# GIO register map
Vendor: Texas Instruments
Peripheral module from a debugger description file (folder ucd3138064).
Registers are 32-bit, access not given, no defined reset value unless marked. A register's access mark holds for its fields unless they carry their own. Offsets are as the file gives them; lines under a group give offsets from that group; [hi:lo] are bit positions; {n}, {i} and the like mark numbered series; 'fields as' and 'values as' point back to an identical list; <NAME> marks a mode.

## GIO
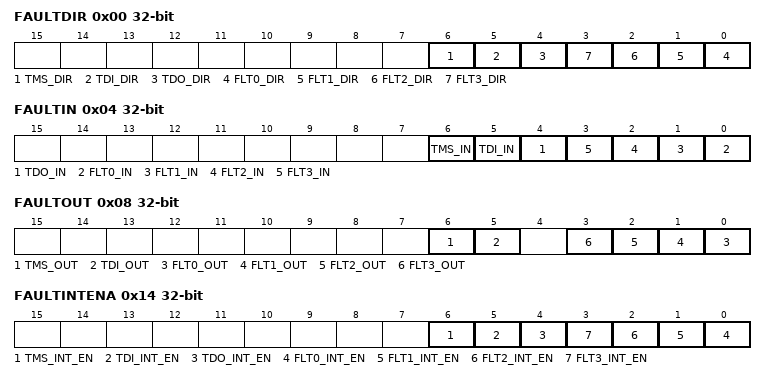
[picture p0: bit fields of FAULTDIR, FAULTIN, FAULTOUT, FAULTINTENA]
0x00 FAULTDIR — Fault Port Direction Register
  [6] TMS_DIR rw — TMS Pin Direction in GPIO Mode
  [5] TDI_DIR rw — TDI Pin Direction in GPIO Mode
  [4] TDO_DIR rw — TDO Pin Direction in GPIO Mode
  [n] FLT{n}_DIR rw (n=0..3) — FAULT[{n}] Pin Direction
0x04 FAULTIN — Fault Port Input Data
  [6] TMS_IN ro — TMS Input Value in GPIO Mode
  [5] TDI_IN ro — TDI Input Value in GPIO Mode
  [4] TDO_IN ro — TDO Input Value in GPIO Mode
  [n] FLT{n}_IN ro (n=0..3) — FAULT[{n}] Input Value
0x08 FAULTOUT — Fault Port Output Data
  [6] TMS_OUT rw — TMS pin output data
  [5] TDI_OUT rw — TDI pin output data
  [n] FLT{n}_OUT rw (n=0..3) — FAULT[{n}] pin output data
0x14 FAULTINTENA — Fault Port Interrupt Enable Register
  [6] TMS_INT_EN rw — TMS pin interrupt enable
  [5] TDI_INT_EN rw — TDI pin interrupt enable
  [4] TDO_INT_EN rw — TDO pin interrupt enable
  [n] FLT{n}_INT_EN rw (n=0..3) — FAULT[{n}] pin interrupt enable
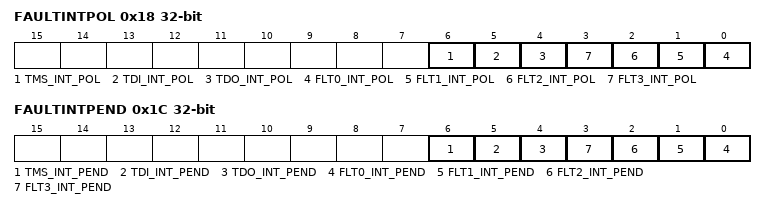
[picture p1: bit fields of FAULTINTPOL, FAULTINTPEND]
0x18 FAULTINTPOL — Fault Port Interrupt Polarity Register
  [6] TMS_INT_POL rw — TMS pin interrupt polarity
  [5] TDI_INT_POL rw — TDI pin interrupt polarity
  [4] TDO_INT_POL rw — TDO pin interrupt polarity
  [n] FLT{n}_INT_POL rw (n=0..3) — FAULT[{n}] pin interrupt polarity
0x1C FAULTINTPEND — Fault Port Interrupt Pending Register
  [6] TMS_INT_PEND rw — TMS pin interrupt flag
  [5] TDI_INT_PEND rw — TDI pin interrupt flag
  [4] TDO_INT_PEND rw — TDO pin interrupt flag
  [n] FLT{n}_INT_PEND rw (n=0..3) — FAULT[{n}] pin interrupt flag
0x20 EXTINTDIR — External Interrupt Direction Register
  [0] EXT_INT_DIR rw — External Interrupt Pin Direction
0x24 EXTINTIN — External Interrupt Input Data
  [0] EXT_INT_IN ro — External Interrupt Pin Input Value
0x28 EXTINTOUT — External Interrupt Output Data
  [0] EXTINT_OUT rw — External Interrupt pin output data
0x34 EXTINTENA — External Interrupt Enable Register
  [0] EXT_INT_EN rw — External Interrupt pin interrupt enable
0x38 EXTINTPOL — External Interrupt Polarity Register
  [0] EXT_INT_POL rw — External Interrupt pin interrupt polarity
0x3C EXTINTPEND — External Interrupt Pending Register
  [0] EXT_INT_PEND rw — External Interrupt pin interrupt flag
